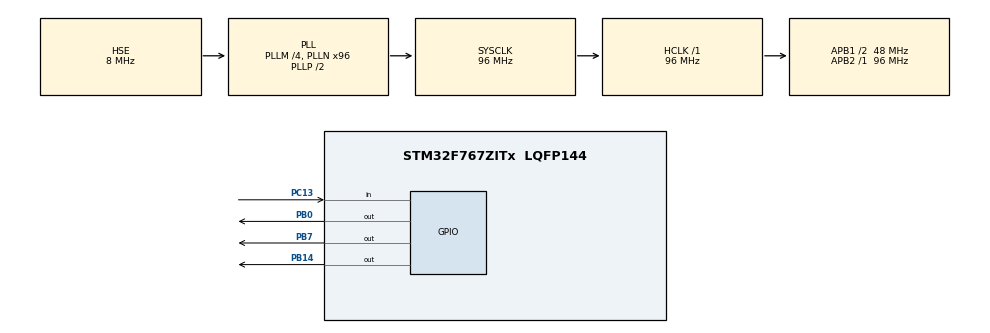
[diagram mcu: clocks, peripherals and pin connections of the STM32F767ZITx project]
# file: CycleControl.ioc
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Mcu.Family=STM32F7
Mcu.Name=STM32F767ZITx
Mcu.Package=LQFP144
NVIC.PriorityGroup=NVIC_PRIORITYGROUP_4
PB0.GPIO_PuPd=GPIO_PULLDOWN
PB0.PinState=GPIO_PIN_SET
PB0.Signal=GPIO_Output
PB14.GPIO_PuPd=GPIO_PULLDOWN
PB14.PinState=GPIO_PIN_SET
PB14.Signal=GPIO_Output
PB7.GPIO_PuPd=GPIO_PULLDOWN
PB7.PinState=GPIO_PIN_SET
PB7.Signal=GPIO_Output
PC13.GPIO_PuPd=GPIO_NOPULL
PC13.Signal=GPIO_Input
PH0/OSC_IN.Mode=HSE-External-Oscillator
PH0/OSC_IN.Signal=RCC_OSC_IN
PH1/OSC_OUT.Mode=HSE-External-Oscillator
PH1/OSC_OUT.Signal=RCC_OSC_OUT
ProjectManager.HeapSize=0x200
ProjectManager.StackSize=0x400
ProjectManager.TargetToolchain=STM32CubeIDE
RCC.48MHZClocksFreq_Value=24000000
RCC.AHBFreq_Value=96000000
RCC.APB1CLKDivider=RCC_HCLK_DIV2
RCC.APB1Freq_Value=48000000
RCC.APB1TimFreq_Value=96000000
RCC.APB2Freq_Value=96000000
RCC.APB2TimFreq_Value=96000000
RCC.CortexFreq_Value=96000000
RCC.HCLKFreq_Value=96000000
RCC.HSE_VALUE=8000000
RCC.HSI_VALUE=16000000
RCC.LSE_VALUE=32768
RCC.PLLM=4
RCC.PLLMUL=RCC_PLL_MUL9
RCC.PLLN=96
RCC.PLLQ=4
RCC.PLLSourceVirtual=RCC_PLLSOURCE_HSE
RCC.PRESCALERUSB=RCC_USBCLKSOURCE_PLL_DIV1_5
RCC.SYSCLKFreq_VALUE=96000000
RCC.SYSCLKSource=RCC_SYSCLKSOURCE_PLLCLK
RCC.SYSCLKSourceVirtual=RCC_SYSCLKSOURCE_PLLCLK
RCC.USBFreq_Value=48000000
RCC.VCOOutputFreq_Value=192000000
board=NUCLEO-F767ZI

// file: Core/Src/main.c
/* USER CODE BEGIN Header */
/**
  ******************************************************************************
  * @file           : main.c
  * @brief          : Main program body
  ******************************************************************************
  * @attention
  *
  * Copyright (c) 2026 STMicroelectronics.
  * All rights reserved.
  *
  * This software is licensed under terms that can be found in the LICENSE file
  * in the root directory of this software component.
  * If no LICENSE file comes with this software, it is provided AS-IS.
  *
  ******************************************************************************
  */
/* USER CODE END Header */
#include "main.h"

/* USER CODE BEGIN PV */
volatile uint8_t led_state = 0;   // LED state machine controlled via USER button (PA0)
/* USER CODE END PV */

void SystemClock_Config(void);
static void MX_GPIO_Init(void);

/* USER CODE BEGIN 0 */
uint8_t lastButton = GPIO_PIN_SET; // button released at startup
/* USER CODE END 0 */

int main(void)
{

  /* MCU Configuration--------------------------------------------------------*/

  /* Reset of all peripherals, Initializes the Flash interface and the Systick. */
  HAL_Init();

  /* Configure the system clock */
  SystemClock_Config();

  /* Initialize all configured peripherals */
  MX_GPIO_Init();

  /* Infinite loop */
  while (1)
  {
      // --- Read USER button (active-low: pressed = RESET) ---
      uint8_t currentButton = HAL_GPIO_ReadPin(GPIOC, GPIO_PIN_13);

      // Detect falling edge (released → pressed)
      if (currentButton == GPIO_PIN_RESET && lastButton == GPIO_PIN_SET)
      {
          led_state = (led_state + 1) % 3; // cycle LED
      }
      lastButton = currentButton;

      // --- Turn all LEDs OFF first (RESET = OFF) ---
      HAL_GPIO_WritePin(GPIOB, GPIO_PIN_0 | GPIO_PIN_7 | GPIO_PIN_14, GPIO_PIN_RESET);

      // --- Turn ON only the selected LED (SET = ON) ---
      if (led_state == 0)
          HAL_GPIO_WritePin(GPIOB, GPIO_PIN_0, GPIO_PIN_SET);  // Green
      else if (led_state == 1)
          HAL_GPIO_WritePin(GPIOB, GPIO_PIN_7, GPIO_PIN_SET);  // Blue
      else if (led_state == 2)
          HAL_GPIO_WritePin(GPIOB, GPIO_PIN_14, GPIO_PIN_SET); // Red

      HAL_Delay(300); // LED ON duration

      // Turn the LED OFF
      HAL_GPIO_WritePin(GPIOB, GPIO_PIN_0 | GPIO_PIN_7 | GPIO_PIN_14, GPIO_PIN_RESET);
      HAL_Delay(300); // LED OFF duration
  }
}

void SystemClock_Config(void)
{
  RCC_OscInitTypeDef RCC_OscInitStruct = {0};
  RCC_ClkInitTypeDef RCC_ClkInitStruct = {0};

  /** Configure the main internal regulator output voltage
  */
  __HAL_RCC_PWR_CLK_ENABLE();
  __HAL_PWR_VOLTAGESCALING_CONFIG(PWR_REGULATOR_VOLTAGE_SCALE3);

  /** Initializes the RCC Oscillators according to the specified parameters
  * in the RCC_OscInitTypeDef structure.
  */
  RCC_OscInitStruct.OscillatorType = RCC_OSCILLATORTYPE_HSE;
  RCC_OscInitStruct.HSEState = RCC_HSE_ON;
  RCC_OscInitStruct.PLL.PLLState = RCC_PLL_ON;
  RCC_OscInitStruct.PLL.PLLSource = RCC_PLLSOURCE_HSE;
  RCC_OscInitStruct.PLL.PLLM = 4;
  RCC_OscInitStruct.PLL.PLLN = 96;
  RCC_OscInitStruct.PLL.PLLP = RCC_PLLP_DIV2;
  RCC_OscInitStruct.PLL.PLLQ = 4;
  RCC_OscInitStruct.PLL.PLLR = 2;
  if (HAL_RCC_OscConfig(&RCC_OscInitStruct) != HAL_OK)
  {
    Error_Handler();
  }

  /** Activate the Over-Drive mode
  */
  if (HAL_PWREx_EnableOverDrive() != HAL_OK)
  {
    Error_Handler();
  }

  /** Initializes the CPU, AHB and APB buses clocks
  */
  RCC_ClkInitStruct.ClockType = RCC_CLOCKTYPE_HCLK|RCC_CLOCKTYPE_SYSCLK
                              |RCC_CLOCKTYPE_PCLK1|RCC_CLOCKTYPE_PCLK2;
  RCC_ClkInitStruct.SYSCLKSource = RCC_SYSCLKSOURCE_PLLCLK;
  RCC_ClkInitStruct.AHBCLKDivider = RCC_SYSCLK_DIV1;
  RCC_ClkInitStruct.APB1CLKDivider = RCC_HCLK_DIV2;
  RCC_ClkInitStruct.APB2CLKDivider = RCC_HCLK_DIV1;

  if (HAL_RCC_ClockConfig(&RCC_ClkInitStruct, FLASH_LATENCY_3) != HAL_OK)
  {
    Error_Handler();
  }
}

static void MX_GPIO_Init(void)
{
  GPIO_InitTypeDef GPIO_InitStruct = {0};

  /* GPIO Ports Clock Enable */
  __HAL_RCC_GPIOC_CLK_ENABLE();
  __HAL_RCC_GPIOH_CLK_ENABLE();
  __HAL_RCC_GPIOB_CLK_ENABLE();

  /*Configure GPIO pin Output Level */
  HAL_GPIO_WritePin(GPIOB, GPIO_PIN_0|GPIO_PIN_14|GPIO_PIN_7, GPIO_PIN_SET);

  /*Configure GPIO pin : PC13 */
  GPIO_InitStruct.Pin = GPIO_PIN_13;
  GPIO_InitStruct.Mode = GPIO_MODE_INPUT;
  GPIO_InitStruct.Pull = GPIO_NOPULL;
  HAL_GPIO_Init(GPIOC, &GPIO_InitStruct);

  /*Configure GPIO pins : PB0 PB14 PB7 */
  GPIO_InitStruct.Pin = GPIO_PIN_0|GPIO_PIN_14|GPIO_PIN_7;
  GPIO_InitStruct.Mode = GPIO_MODE_OUTPUT_PP;
  GPIO_InitStruct.Pull = GPIO_PULLDOWN;
  GPIO_InitStruct.Speed = GPIO_SPEED_FREQ_LOW;
  HAL_GPIO_Init(GPIOB, &GPIO_InitStruct);

}

void Error_Handler(void)
{
  __disable_irq();
  while (1)
  {
  }
}
